# BlueNRG_LPF register map
File version: 1.0
CPU: CM0+ r0p0, little endian, no MPU, no FPU, 2 interrupt priority bits
Registers are 32-bit, read-write, reset 0x0 unless marked. A register's access mark holds for its fields unless they carry their own. Offsets are from the block's base; [hi:lo] are bit positions; 'fields as' and 'values as' point back to an identical list.

## RRM
Base 0x60001400
0x10 UDRA_CTRL0 — UDRA control register
  [0] RELOAD_RDCFGPTR
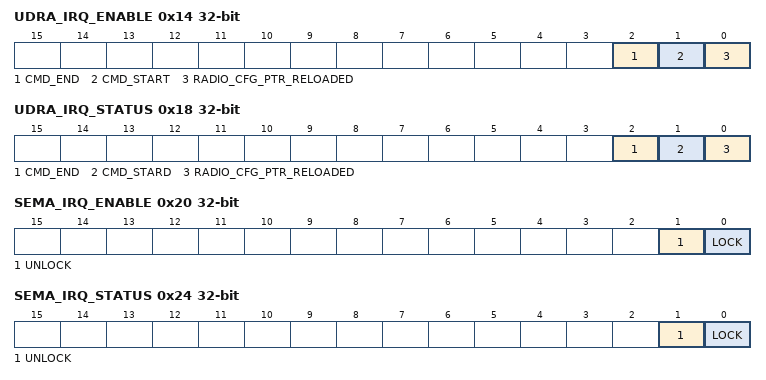
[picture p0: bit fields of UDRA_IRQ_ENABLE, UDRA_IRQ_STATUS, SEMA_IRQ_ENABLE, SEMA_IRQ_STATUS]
0x14 UDRA_IRQ_ENABLE — UDRA Interrupt mask register
  [2] CMD_END, [1] CMD_START, [0] RADIO_CFG_PTR_RELOADED
0x18 UDRA_IRQ_STATUS — UDRA Interrupt status register
  [2] CMD_END, [1] CMD_STARD, [0] RADIO_CFG_PTR_RELOADED
0x1C UDRA_RADIO_CFG_PTR ro — UDRA radio configuration pointer register
  [31:0] RADIO_CONFIG_ADDRESS
0x20 SEMA_IRQ_ENABLE — Semaphore Interrupt mask register
  [1] UNLOCK, [0] LOCK
0x24 SEMA_IRQ_STATUS — Semaphore Interrupt status register
  [1] UNLOCK, [0] LOCK
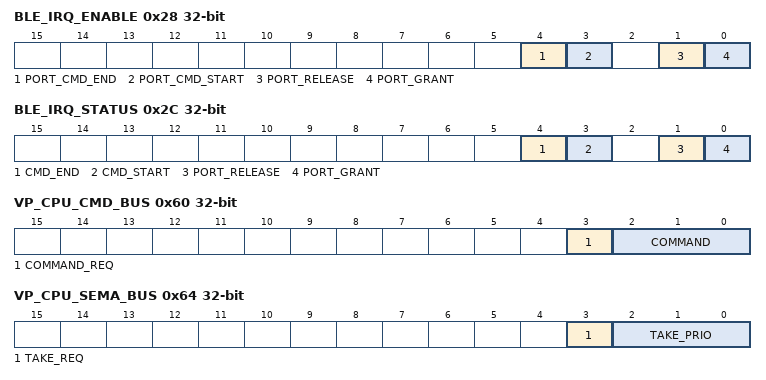
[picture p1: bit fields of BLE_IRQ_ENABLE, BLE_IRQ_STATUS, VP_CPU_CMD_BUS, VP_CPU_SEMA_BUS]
0x28 BLE_IRQ_ENABLE — IP_BLE IT mask register
  [4] PORT_CMD_END, [3] PORT_CMD_START, [1] PORT_RELEASE, [0] PORT_GRANT
0x2C BLE_IRQ_STATUS — IP_BLE IT status register
  [4] CMD_END, [3] CMD_START, [1] PORT_RELEASE, [0] PORT_GRANT
0x60 VP_CPU_CMD_BUS — CPU Virtual Port Command bus register
  [3] COMMAND_REQ, [2:0] COMMAND
0x64 VP_CPU_SEMA_BUS — CPU Virtual Port semaphore bus register
  [3] TAKE_REQ, [2:0] TAKE_PRIO
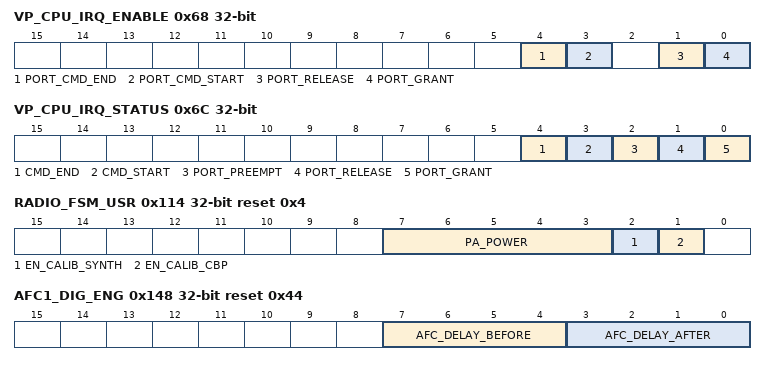
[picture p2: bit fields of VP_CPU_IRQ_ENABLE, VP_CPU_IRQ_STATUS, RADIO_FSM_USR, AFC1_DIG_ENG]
0x68 VP_CPU_IRQ_ENABLE — CPU Virtual Port Interrupt mask register
  fields as BLE_IRQ_ENABLE
0x6C VP_CPU_IRQ_STATUS — CPU Virtual Port Interrupt status register
  [4] CMD_END, [3] CMD_START, [2] PORT_PREEMPT, [1] PORT_RELEASE, [0] PORT_GRANT
0x100 AA0_DIG_USR reset 0xD6 — access address register
  [7:0] AA_7_0
0x104 AA1_DIG_USR reset 0xBE — access address register
  [7:0] AA_15_8
0x108 AA2_DIG_USR reset 0x89 — access address register
  [7:0] AA_23_16
0x10C AA3_DIG_USR reset 0x8E — access address register
  [7:0] AA_31_24
0x110 DEM_MOD_DIG_USR reset 0x26 — MOD DEM DIG USR register
  [7:1] CHANNEL_NUM
0x114 RADIO_FSM_USR reset 0x4
  [7:3] PA_POWER, [2] EN_CALIB_SYNTH, [1] EN_CALIB_CBP
0x118 PHYCTRL_DIG_USR
  [2:0] RXTXPHY
0x148 AFC1_DIG_ENG reset 0x44
  [7:4] AFC_DELAY_BEFORE, [3:0] AFC_DELAY_AFTER
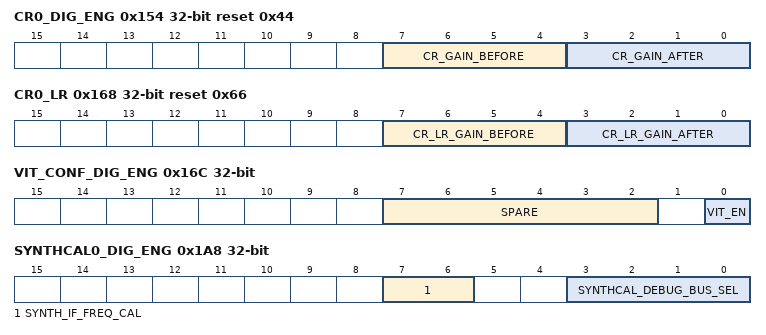
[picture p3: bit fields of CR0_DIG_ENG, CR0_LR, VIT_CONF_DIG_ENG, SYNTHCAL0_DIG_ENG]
0x154 CR0_DIG_ENG reset 0x44
  [7:4] CR_GAIN_BEFORE, [3:0] CR_GAIN_AFTER
0x168 CR0_LR reset 0x66
  [7:4] CR_LR_GAIN_BEFORE, [3:0] CR_LR_GAIN_AFTER
0x16C VIT_CONF_DIG_ENG
  [7:2] SPARE, [0] VIT_EN
0x184 LR_PD_THR_DIG_ENG reset 0x50
  [7:0] LR_PD_THR
0x188 LR_RSSI_THR_DIG_ENG reset 0x1B
  [7:0] LR_RSSI_THR
0x18C LR_AAC_THR_DIG_ENG reset 0x38
  [7:0] LR_AAC_THR
0x1A8 SYNTHCAL0_DIG_ENG
  [7:6] SYNTH_IF_FREQ_CAL, [3:0] SYNTHCAL_DEBUG_BUS_SEL
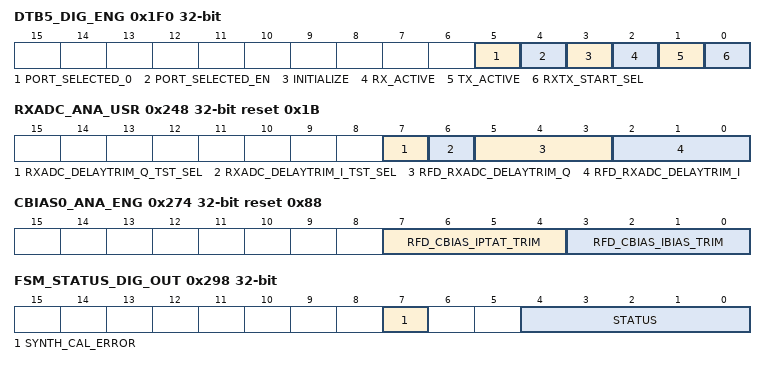
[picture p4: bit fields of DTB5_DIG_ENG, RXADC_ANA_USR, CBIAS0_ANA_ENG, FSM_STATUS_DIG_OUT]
0x1F0 DTB5_DIG_ENG
  [5] PORT_SELECTED_0, [4] PORT_SELECTED_EN, [3] INITIALIZE, [2] RX_ACTIVE, [1] TX_ACTIVE, [0] RXTX_START_SEL
0x248 RXADC_ANA_USR reset 0x1B
  [7] RXADC_DELAYTRIM_Q_TST_SEL, [6] RXADC_DELAYTRIM_I_TST_SEL, [5:3] RFD_RXADC_DELAYTRIM_Q, [2:0] RFD_RXADC_DELAYTRIM_I
0x254 LDO_ANA_ENG
  [0] RFD_RF_REG_BYPASS
0x274 CBIAS0_ANA_ENG reset 0x88
  [7:4] RFD_CBIAS_IPTAT_TRIM, [3:0] RFD_CBIAS_IBIAS_TRIM
0x278 CBIAS1_ANA_ENG
  [7] CBIAS0_TRIM_TST_SEL
0x280 SYNTHCAL0_DIG_OUT ro
  [6:0] VCO_CALAMP_OUT_6_0
0x284 SYNTHCAL1_DIG_OUT ro reset 0x1
  [3:0] VCO_CALAMP_OUT_10_7
0x288 SYNTHCAL2_DIG_OUT ro reset 0x40
  [6:0] VCO_CALFREQ_OUT
0x28C SYNTHCAL3_DIG_OUT ro
  [7:0] SYNTHCAL_DEBUG_BUS
0x290 SYNTHCAL4_DIG_OUT ro reset 0x18
  [5:0] MOD_REF_DAC_WORD_OUT
0x294 SYNTHCAL5_DIG_OUT ro reset 0x7
  [3:0] CBP_CALIB_WORD
0x298 FSM_STATUS_DIG_OUT ro
  [7] SYNTH_CAL_ERROR, [4:0] STATUS
0x2A4 RSSI0_DIG_OUT ro reset 0x8
  [7:0] RSSI_MEAS_OUT_7_0
0x2A8 RSSI1_DIG_OUT ro reset 0x8
  [7:0] RSSI_MEAS_OUT_15_8
0x2AC AGC_DIG_OUT ro
  [3:0] AGC_ATT_OUT
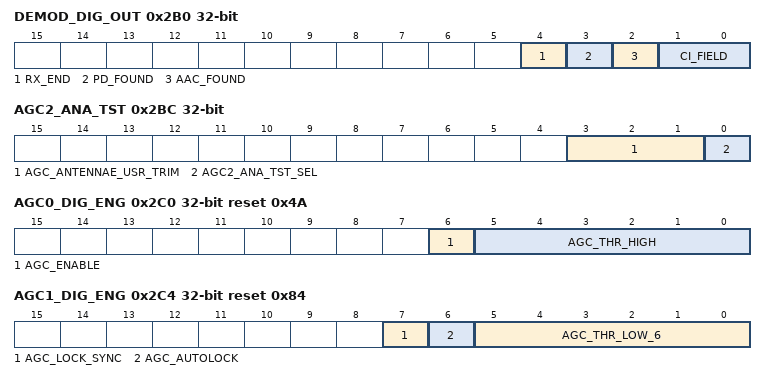
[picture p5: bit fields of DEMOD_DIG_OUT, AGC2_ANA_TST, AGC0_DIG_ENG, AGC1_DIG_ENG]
0x2B0 DEMOD_DIG_OUT ro
  [4] RX_END, [3] PD_FOUND, [2] AAC_FOUND, [1:0] CI_FIELD
0x2BC AGC2_ANA_TST
  [3:1] AGC_ANTENNAE_USR_TRIM, [0] AGC2_ANA_TST_SEL
0x2C0 AGC0_DIG_ENG reset 0x4A
  [6] AGC_ENABLE, [5:0] AGC_THR_HIGH
0x2C4 AGC1_DIG_ENG reset 0x84
  [7] AGC_LOCK_SYNC, [6] AGC_AUTOLOCK, [5:0] AGC_THR_LOW_6
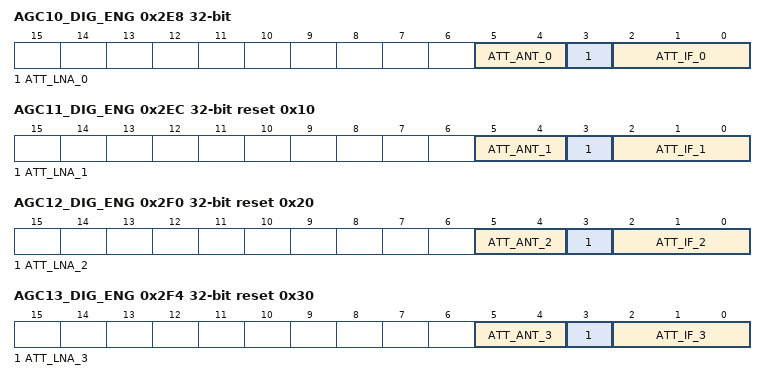
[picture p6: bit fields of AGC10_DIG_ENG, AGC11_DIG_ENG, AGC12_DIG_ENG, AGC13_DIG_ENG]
0x2E8 AGC10_DIG_ENG — Mapping for AGC step 0
  [5:4] ATT_ANT_0, [3] ATT_LNA_0, [2:0] ATT_IF_0
0x2EC AGC11_DIG_ENG reset 0x10 — Mapping for AGC step 1
  [5:4] ATT_ANT_1, [3] ATT_LNA_1, [2:0] ATT_IF_1
0x2F0 AGC12_DIG_ENG reset 0x20 — Mapping for AGC step 2
  [5:4] ATT_ANT_2, [3] ATT_LNA_2, [2:0] ATT_IF_2
0x2F4 AGC13_DIG_ENG reset 0x30 — Mapping for AGC step 3
  [5:4] ATT_ANT_3, [3] ATT_LNA_3, [2:0] ATT_IF_3
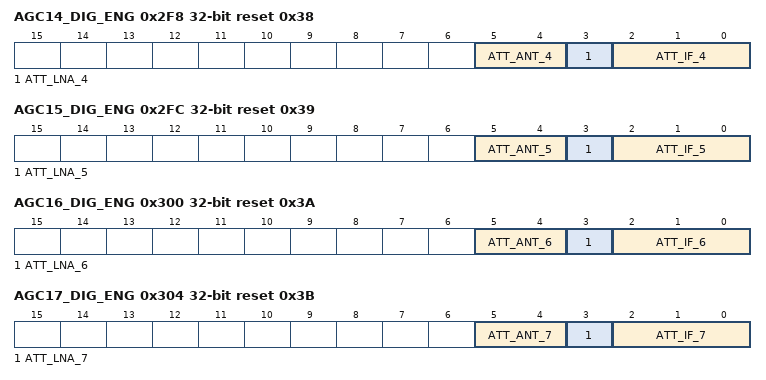
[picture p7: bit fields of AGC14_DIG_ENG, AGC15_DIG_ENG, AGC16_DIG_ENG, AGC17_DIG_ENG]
0x2F8 AGC14_DIG_ENG reset 0x38 — Mapping for AGC step 4
  [5:4] ATT_ANT_4, [3] ATT_LNA_4, [2:0] ATT_IF_4
0x2FC AGC15_DIG_ENG reset 0x39 — Mapping for AGC step 5
  [5:4] ATT_ANT_5, [3] ATT_LNA_5, [2:0] ATT_IF_5
0x300 AGC16_DIG_ENG reset 0x3A — Mapping for AGC step 6
  [5:4] ATT_ANT_6, [3] ATT_LNA_6, [2:0] ATT_IF_6
0x304 AGC17_DIG_ENG reset 0x3B — Mapping for AGC step 7
  [5:4] ATT_ANT_7, [3] ATT_LNA_7, [2:0] ATT_IF_7
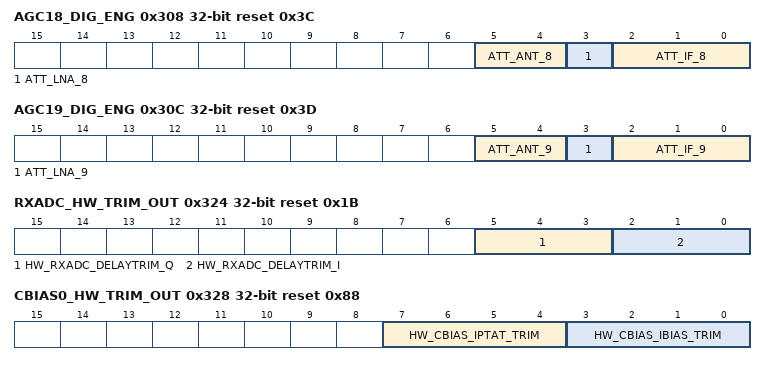
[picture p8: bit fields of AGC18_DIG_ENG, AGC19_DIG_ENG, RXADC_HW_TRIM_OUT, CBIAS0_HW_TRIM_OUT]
0x308 AGC18_DIG_ENG reset 0x3C — Mapping for AGC step 8
  [5:4] ATT_ANT_8, [3] ATT_LNA_8, [2:0] ATT_IF_8
0x30C AGC19_DIG_ENG reset 0x3D — Mapping for AGC step 9
  [5:4] ATT_ANT_9, [3] ATT_LNA_9, [2:0] ATT_IF_9
0x324 RXADC_HW_TRIM_OUT ro reset 0x1B
  [5:3] HW_RXADC_DELAYTRIM_Q, [2:0] HW_RXADC_DELAYTRIM_I
0x328 CBIAS0_HW_TRIM_OUT ro reset 0x88
  [7:4] HW_CBIAS_IPTAT_TRIM, [3:0] HW_CBIAS_IBIAS_TRIM
0x330 AGC_HW_TRIM_OUT ro reset 0x6
  [3:1] HW_AGC_ANTENNAE_TRIM
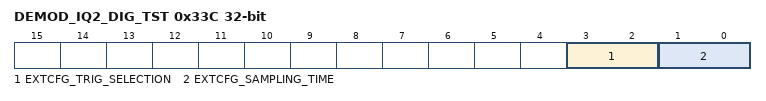
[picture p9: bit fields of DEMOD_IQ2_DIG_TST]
0x33C DEMOD_IQ2_DIG_TST
  [3:2] EXTCFG_TRIG_SELECTION, [1:0] EXTCFG_SAMPLING_TIME
0x340 ANTSW_DIG0_USR reset 0x1C
  [6:0] RX_TIME_TO_SAMPLE
0x344 ANTSW_DIG1_USR reset 0xB
  [5:0] RX_TIME_TO_SWITCH
0x348 ANTSW_DIG2_USR reset 0x29
  [6:0] TX_TIME_TO_SWITCH
0x34C ANTSW_DIG3_USR reset 0x23
  [6:0] TX_TIME_TO_SWITCH_2M
